# AT32UC3L016 device description
Architecture: AVR32_UC3; Family: AVR UC3
Registers are 32-bit, read-write, reset 0x0 unless marked. A register's access mark holds for its fields unless they carry their own. Offsets are from the block's base; [hi:lo] are bit positions; lines under a group give offsets from that group; {n}, {i} and the like mark numbered series.

## GPIO — General Purpose Input/Output Controller
Instances: GPIO 0xffff2c00
{0x0+0x200*i} port[{i}] (i=0..63) group
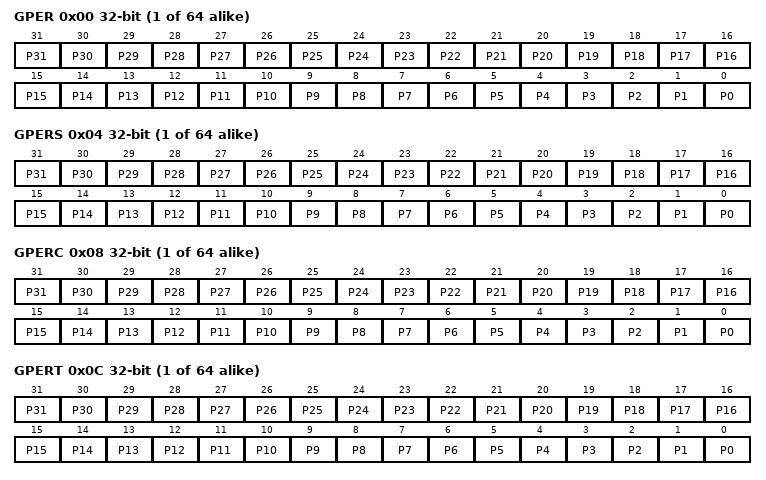
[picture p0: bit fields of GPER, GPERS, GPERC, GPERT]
  0x00 GPER — GPIO Enable Register
    [n] P{n} (n=0..31)
  0x04 GPERS wo reset not defined — GPIO Enable Register - Set
    [n] P{n} (n=0..31)
  0x08 GPERC wo reset not defined — GPIO Enable Register - Clear
    [n] P{n} (n=0..31)
  0x0C GPERT wo reset not defined — GPIO Enable Register - Toggle
    [n] P{n} (n=0..31)
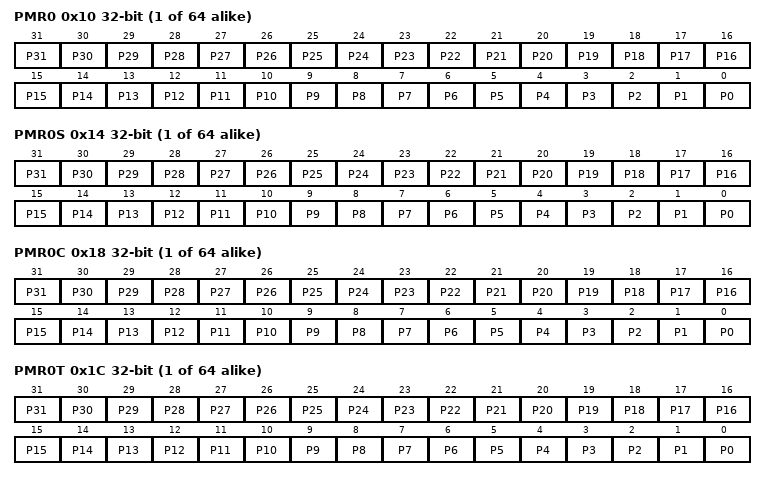
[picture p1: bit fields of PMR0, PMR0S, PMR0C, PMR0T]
  0x10 PMR0 — Peripheral Mux Register 0
    [n] P{n} (n=0..31)
  0x14 PMR0S wo reset not defined — Peripheral Mux Register 0 - Set
    [n] P{n} (n=0..31)
  0x18 PMR0C wo reset not defined — Peripheral Mux Register 0 - Clear
    [n] P{n} (n=0..31)
  0x1C PMR0T wo reset not defined — Peripheral Mux Register 0 - Toggle
    [n] P{n} (n=0..31)
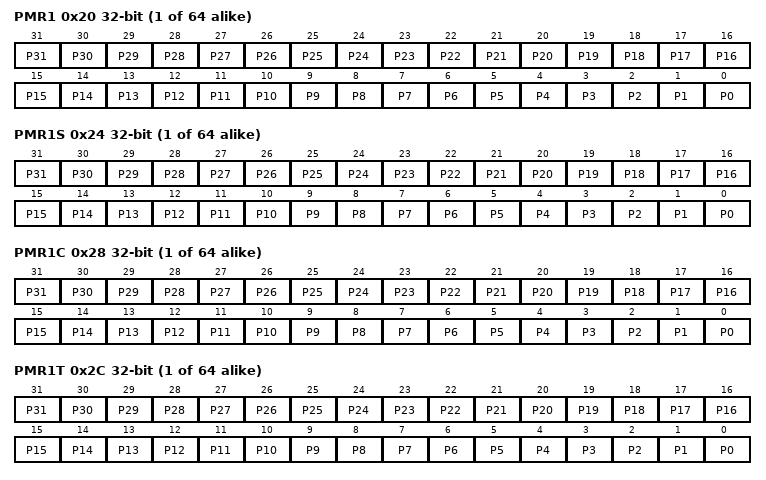
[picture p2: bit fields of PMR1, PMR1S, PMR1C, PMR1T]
  0x20 PMR1 — Peripheral Mux Register 1
    [n] P{n} (n=0..31)
  0x24 PMR1S wo reset not defined — Peripheral Mux Register 1 - Set
    [n] P{n} (n=0..31)
  0x28 PMR1C wo reset not defined — Peripheral Mux Register 1 - Clear
    [n] P{n} (n=0..31)
  0x2C PMR1T wo reset not defined — Peripheral Mux Register 1 - Toggle
    [n] P{n} (n=0..31)
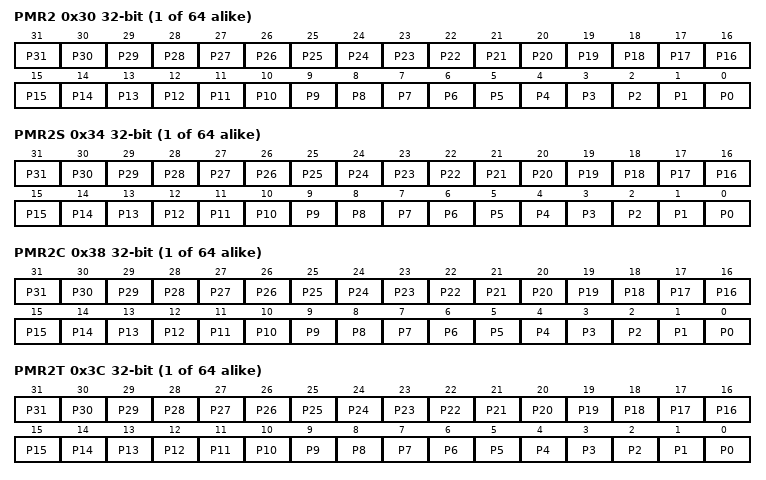
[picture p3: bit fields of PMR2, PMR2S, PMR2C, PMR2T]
  0x30 PMR2 — Peripheral Mux Register 1
    [n] P{n} (n=0..31)
  0x34 PMR2S wo reset not defined — Peripheral Mux Register 1 - Set
    [n] P{n} (n=0..31)
  0x38 PMR2C wo reset not defined — Peripheral Mux Register 1 - Clear
    [n] P{n} (n=0..31)
  0x3C PMR2T wo reset not defined — Peripheral Mux Register 1 - Toggle
    [n] P{n} (n=0..31)
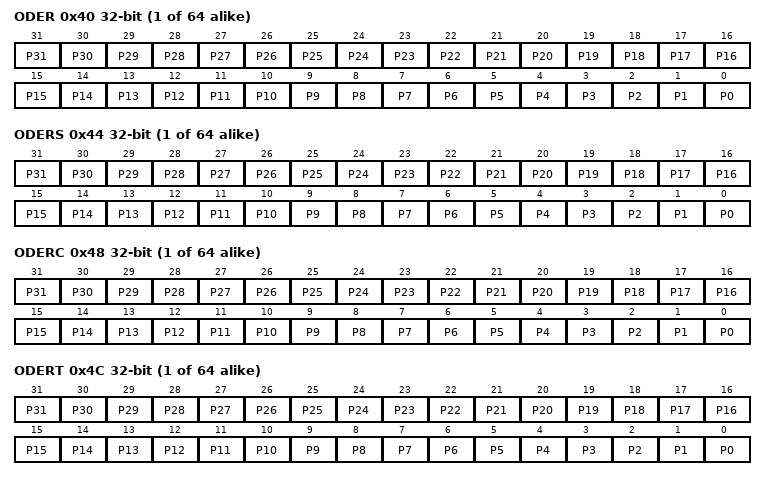
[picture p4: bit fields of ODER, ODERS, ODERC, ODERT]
  0x40 ODER — Output Driver Enable Register
    [n] P{n} (n=0..31)
  0x44 ODERS wo reset not defined — Output Driver Enable Register - Set
    [n] P{n} (n=0..31)
  0x48 ODERC wo reset not defined — Output Driver Enable Register - Clear
    [n] P{n} (n=0..31)
  0x4C ODERT wo reset not defined — Output Driver Enable Register - Toggle
    [n] P{n} (n=0..31)
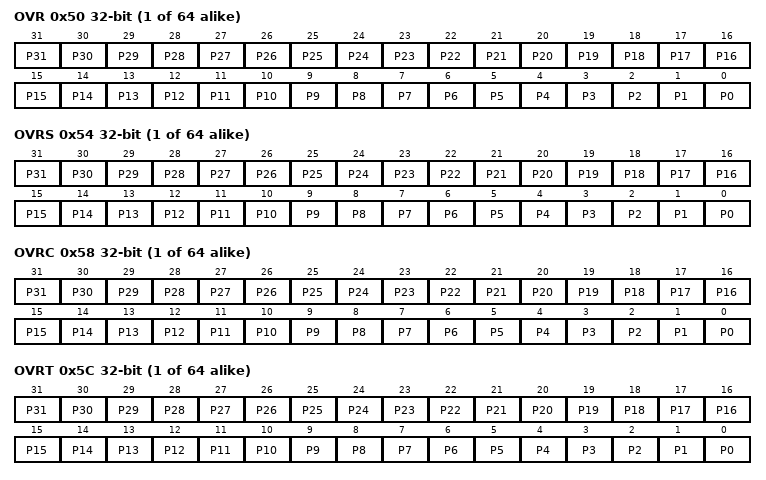
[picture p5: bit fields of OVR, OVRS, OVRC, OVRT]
  0x50 OVR — Output Value Register
    [n] P{n} (n=0..31)
  0x54 OVRS wo reset not defined — Output Value Register - Set
    [n] P{n} (n=0..31)
  0x58 OVRC wo reset not defined — Output Value Register - Clear
    [n] P{n} (n=0..31)
  0x5C OVRT wo reset not defined — Output Value Register - Toggle
    [n] P{n} (n=0..31)
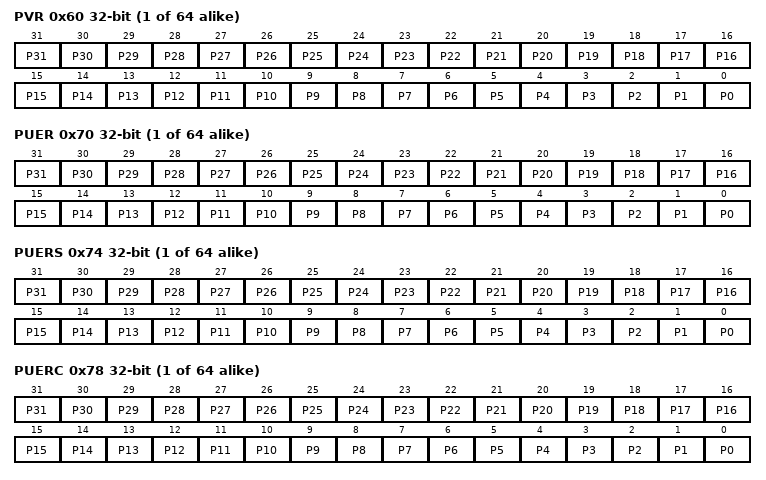
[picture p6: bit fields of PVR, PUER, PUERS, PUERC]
  0x60 PVR ro — Pin Value Register
    [n] P{n} (n=0..31)
  0x70 PUER — Pull-up Enable Register
    [n] P{n} (n=0..31)
  0x74 PUERS wo reset not defined — Pull-up Enable Register - Set
    [n] P{n} (n=0..31)
  0x78 PUERC wo reset not defined — Pull-up Enable Register - Clear
    [n] P{n} (n=0..31)
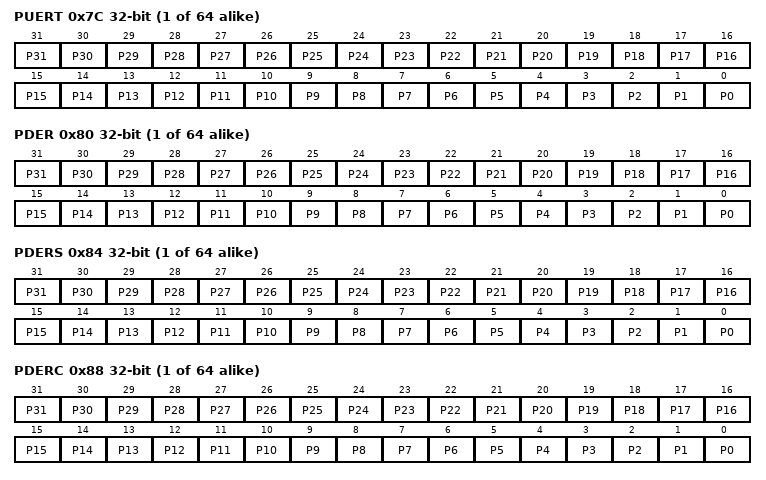
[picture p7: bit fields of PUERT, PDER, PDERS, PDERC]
  0x7C PUERT wo reset not defined — Pull-up Enable Register - Toggle
    [n] P{n} (n=0..31)
  0x80 PDER — Pull-down Enable Register
    [n] P{n} (n=0..31)
  0x84 PDERS wo reset not defined — Pull-down Enable Register - Set
    [n] P{n} (n=0..31)
  0x88 PDERC wo reset not defined — Pull-down Enable Register - Clear
    [n] P{n} (n=0..31)
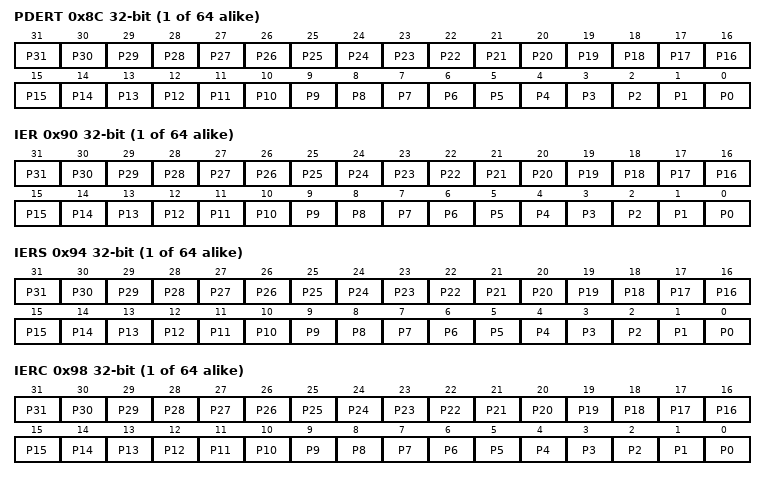
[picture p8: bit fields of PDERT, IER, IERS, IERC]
  0x8C PDERT wo reset not defined — Pull-down Enable Register - Toggle
    [n] P{n} (n=0..31)
  0x90 IER — Interrupt Enable Register
    [n] P{n} (n=0..31)
  0x94 IERS wo reset not defined — Interrupt Enable Register - Set
    [n] P{n} (n=0..31)
  0x98 IERC wo reset not defined — Interrupt Enable Register - Clear
    [n] P{n} (n=0..31)
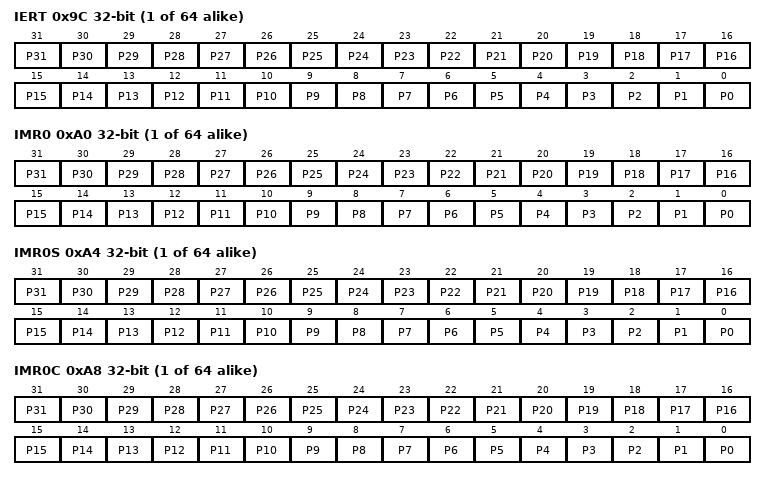
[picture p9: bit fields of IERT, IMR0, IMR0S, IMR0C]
  0x9C IERT wo reset not defined — Interrupt Enable Register - Toggle
    [n] P{n} (n=0..31)
  0xA0 IMR0 — Interrupt Mode Register 0
    [n] P{n} (n=0..31)
  0xA4 IMR0S wo reset not defined — Interrupt Mode Register 0 - Set
    [n] P{n} (n=0..31)
  0xA8 IMR0C wo reset not defined — Interrupt Mode Register 0 - Clear
    [n] P{n} (n=0..31)
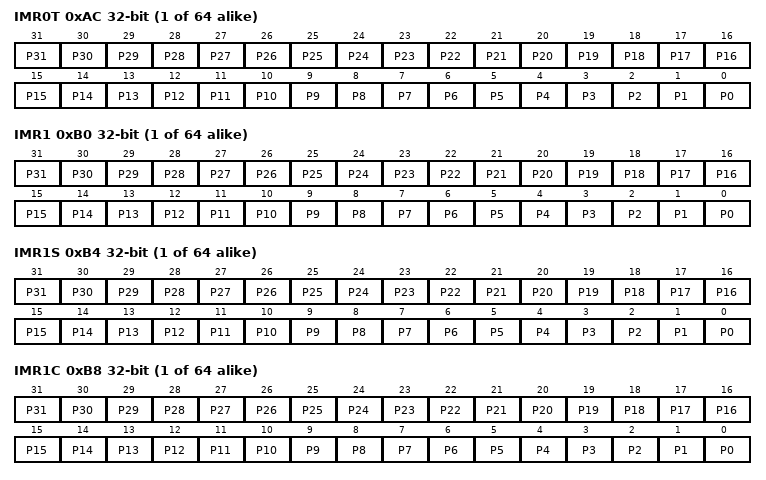
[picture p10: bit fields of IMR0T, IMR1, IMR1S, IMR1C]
  0xAC IMR0T wo reset not defined — Interrupt Mode Register 0 - Toggle
    [n] P{n} (n=0..31)
  0xB0 IMR1 — Interrupt Mode Register 1
    [n] P{n} (n=0..31)
  0xB4 IMR1S wo reset not defined — Interrupt Mode Register 1 - Set
    [n] P{n} (n=0..31)
  0xB8 IMR1C wo reset not defined — Interrupt Mode Register 1 - Clear
    [n] P{n} (n=0..31)
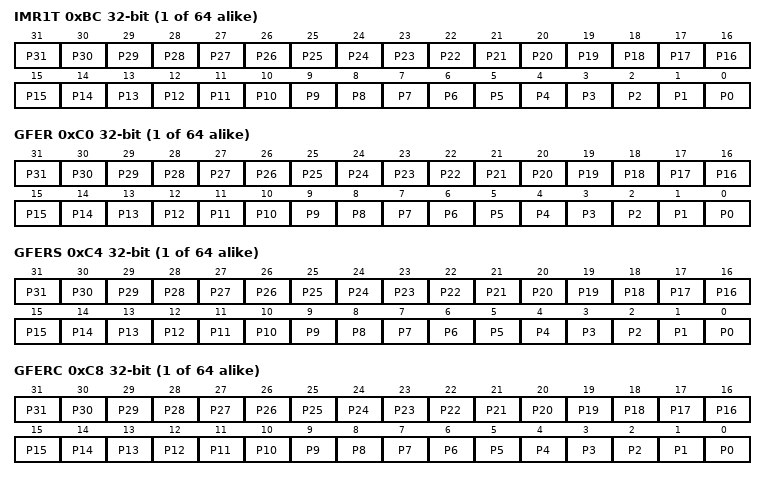
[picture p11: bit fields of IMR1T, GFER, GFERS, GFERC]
  0xBC IMR1T wo reset not defined — Interrupt Mode Register 1 - Toggle
    [n] P{n} (n=0..31)
  0xC0 GFER — Glitch Filter Enable Register
    [n] P{n} (n=0..31)
  0xC4 GFERS wo reset not defined — Glitch Filter Enable Register - Set
    [n] P{n} (n=0..31)
  0xC8 GFERC wo reset not defined — Glitch Filter Enable Register - Clear
    [n] P{n} (n=0..31)
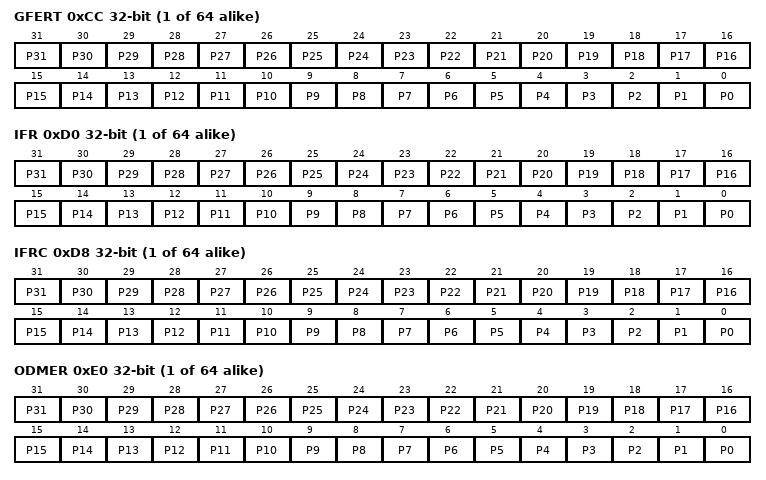
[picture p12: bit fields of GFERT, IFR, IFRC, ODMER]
  0xCC GFERT wo reset not defined — Glitch Filter Enable Register - Toggle
    [n] P{n} (n=0..31)
  0xD0 IFR ro — Interrupt Flag Register
    [n] P{n} (n=0..31)
  0xD8 IFRC wo reset not defined — Interrupt Flag Register - Clear
    [n] P{n} (n=0..31)
  0xE0 ODMER — Open Drain Mode Register
    [n] P{n} (n=0..31)
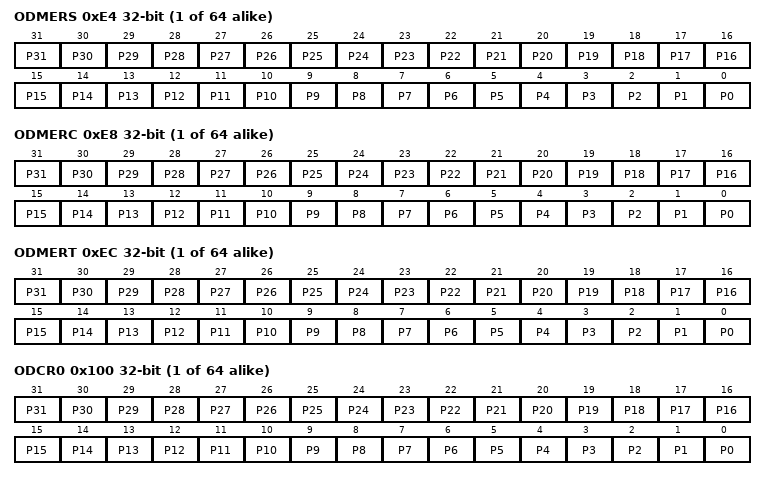
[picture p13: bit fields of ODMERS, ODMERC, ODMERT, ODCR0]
  0xE4 ODMERS wo reset not defined — Open Drain Mode Register - Set
    [n] P{n} (n=0..31)
  0xE8 ODMERC wo reset not defined — Open Drain Mode Register - Clear
    [n] P{n} (n=0..31)
  0xEC ODMERT wo reset not defined — Open Drain Mode Register - Toggle
    [n] P{n} (n=0..31)
  0x100 ODCR0 — Output Driving Capability Register 0
    [n] P{n} (n=0..31)
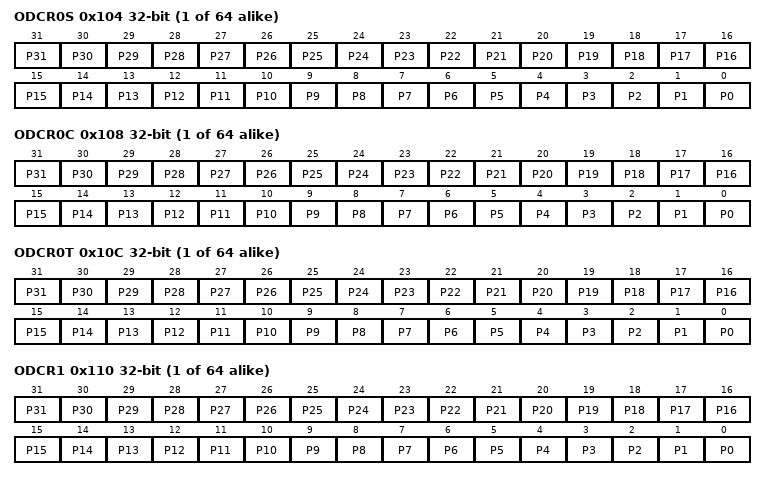
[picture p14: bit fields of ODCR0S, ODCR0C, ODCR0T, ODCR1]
  0x104 ODCR0S — Output Driving Capability Register 0 - Set
    [n] P{n} (n=0..31)
  0x108 ODCR0C — Output Driving Capability Register 0 - Clear
    [n] P{n} (n=0..31)
  0x10C ODCR0T — Output Driving Capability Register 0 - Toggle
    [n] P{n} (n=0..31)
  0x110 ODCR1 — Output Driving Capability Register 1
    [n] P{n} (n=0..31)
  0x114 ODCR1S — Output Driving Capability Register 1 - Set
    [n] P{n} (n=0..31)
  0x118 ODCR1C — Output Driving Capability Register 1 - Clear
    [n] P{n} (n=0..31)
  0x11C ODCR1T — Output Driving Capability Register 1 - Toggle
    [n] P{n} (n=0..31)
  0x130 OSRR0 — Output Slew Rate Register 0
    [n] P{n} (n=0..31)
  0x134 OSRR0S — Output Slew Rate Register 0 - Set
    [n] P{n} (n=0..31)
  0x138 OSRR0C — Output Slew Rate Register 0 - Clear
    [n] P{n} (n=0..31)
  0x13C OSRR0T — Output Slew Rate Register 0 - Toggle
    [n] P{n} (n=0..31)
  0x160 STER — Schmitt Trigger Enable Register
    [n] P{n} (n=0..31)
  0x164 STERS — Schmitt Trigger Enable Register - Set
    [n] P{n} (n=0..31)
  0x168 STERC — Schmitt Trigger Enable Register - Clear
    [n] P{n} (n=0..31)
  0x16C STERT — Schmitt Trigger Enable Register - Toggle
    [n] P{n} (n=0..31)
  0x180 EVER — Event Enable Register
    [n] P{n} (n=0..31)
  0x184 EVERS wo — Event Enable Register - Set
    [n] P{n} (n=0..31)
  0x188 EVERC wo — Event Enable Register - Clear
    [n] P{n} (n=0..31)
  0x18C EVERT wo — Event Enable Register - Toggle
    [n] P{n} (n=0..31)
  0x1A0 LOCK — Lock Register 0
    [n] P{n} (n=0..31)
  0x1A4 LOCKS wo — Lock Register 0 - Set
    [n] P{n} (n=0..31)
  0x1A8 LOCKC wo — Lock Register 0 - Clear
    [n] P{n} (n=0..31)
  0x1AC LOCKT wo — Lock Register 0 - Toggle
    [n] P{n} (n=0..31)
  0x1E0 UNLOCK wo — Unlock Register 0
    [31:24] KEY — Unlocking Key
    [9:0] OFFSET
  0x1E4 ASR — Access Status Register 0
    [0] AR — Access Error
  0x1FC VERSION ro reset 0x200
